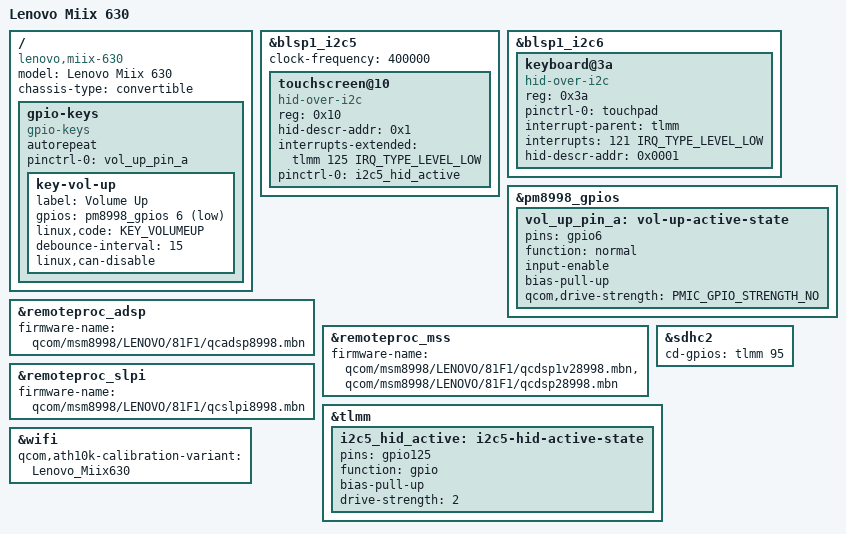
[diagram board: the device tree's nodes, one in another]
// SPDX-License-Identifier: GPL-2.0
/* Copyright (c) 2019, Jeffrey Hugo. All rights reserved. */

/dts-v1/;

#include <dt-bindings/pinctrl/qcom,pmic-gpio.h>
#include "msm8998-clamshell.dtsi"

/ {
	model = "Lenovo Miix 630";
	compatible = "lenovo,miix-630", "qcom,msm8998";
	chassis-type = "convertible";

	gpio-keys {
		compatible = "gpio-keys";
		autorepeat;

		pinctrl-0 = <&vol_up_pin_a>;
		pinctrl-names = "default";

		key-vol-up {
			label = "Volume Up";
			gpios = <&pm8998_gpios 6 GPIO_ACTIVE_LOW>;
			linux,code = <KEY_VOLUMEUP>;
			debounce-interval = <15>;
			linux,can-disable;
		};
	};
};

&blsp1_i2c5 {
	clock-frequency = <400000>;
	status = "okay";

	touchscreen@10 {
		compatible = "hid-over-i2c";
		reg = <0x10>;
		hid-descr-addr = <0x1>;

		interrupts-extended = <&tlmm 125 IRQ_TYPE_LEVEL_LOW>;

		pinctrl-0 = <&i2c5_hid_active>;
		pinctrl-names = "default";
	};
};

&blsp1_i2c6 {
	status = "okay";

	keyboard@3a {
		compatible = "hid-over-i2c";
		reg = <0x3a>;
		pinctrl-names = "default";
		pinctrl-0 = <&touchpad>;

		interrupt-parent = <&tlmm>;
		interrupts = <121 IRQ_TYPE_LEVEL_LOW>;

		hid-descr-addr = <0x0001>;
	};
};

&pm8998_gpios {
	vol_up_pin_a: vol-up-active-state {
		pins = "gpio6";
		function = "normal";
		input-enable;
		bias-pull-up;
		qcom,drive-strength = <PMIC_GPIO_STRENGTH_NO>;
	};
};

&remoteproc_adsp {
	firmware-name = "qcom/msm8998/LENOVO/81F1/qcadsp8998.mbn";

	status = "okay";
};

&remoteproc_mss {
	firmware-name = "qcom/msm8998/LENOVO/81F1/qcdsp1v28998.mbn",
			"qcom/msm8998/LENOVO/81F1/qcdsp28998.mbn";
};

&remoteproc_slpi {
	firmware-name = "qcom/msm8998/LENOVO/81F1/qcslpi8998.mbn";

	status = "okay";
};

&sdhc2 {
	cd-gpios = <&tlmm 95 GPIO_ACTIVE_HIGH>;
};

&tlmm {
	i2c5_hid_active: i2c5-hid-active-state {
		pins = "gpio125";
		function = "gpio";
		bias-pull-up;
		drive-strength = <2>;
	};
};

&wifi {
	qcom,ath10k-calibration-variant = "Lenovo_Miix630";
};
